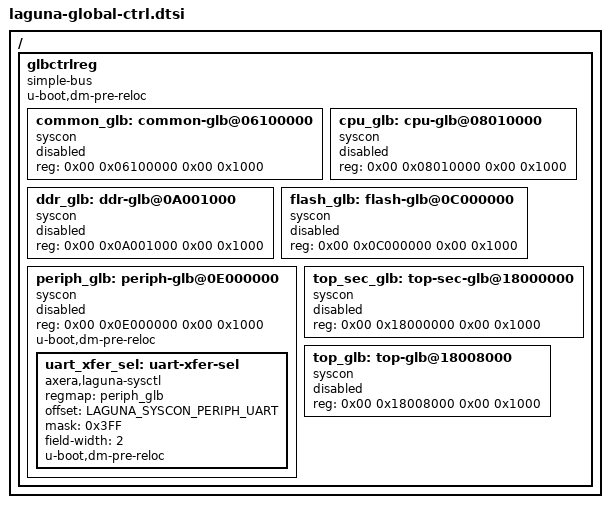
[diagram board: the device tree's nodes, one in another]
/* SPDX-License-Identifier: GPL-2.0+
 *
 * Device Tree Source for each subsystem global register region
 *
 * Copyright (C) 2024 Charleye <wangkart@aliyun.com>
 */

/ {
	glbctrlreg {
		compatible = "simple-bus";
		#address-cells = <2>;
		#size-cells = <2>;
		u-boot,dm-pre-reloc;
		u-boot,dm-spl;
		ranges;

		common_glb: common-glb@06100000 {
			compatible = "syscon", "simple-mfd";
			reg = <0x00 0x06100000 0x00 0x1000>;
			#address-cells = <1>;
			#size-cells = <1>;
			status = "disabled";
		};

		cpu_glb: cpu-glb@08010000 {
			compatible = "syscon", "simple-mfd";
			reg = <0x00 0x08010000 0x00 0x1000>;
			#address-cells = <1>;
			#size-cells = <1>;
			status = "disabled";
		};

		ddr_glb: ddr-glb@0A001000 {
			compatible = "syscon", "simple-mfd";
			reg = <0x00 0x0A001000 0x00 0x1000>;
			#address-cells = <1>;
			#size-cells = <1>;
			status = "disabled";
		};

		flash_glb: flash-glb@0C000000 {
			compatible = "syscon", "simple-mfd";
			reg = <0x00 0x0C000000 0x00 0x1000>;
			#address-cells = <1>;
			#size-cells = <1>;
			status = "disabled";
		};

		periph_glb: periph-glb@0E000000 {
			compatible = "syscon", "simple-mfd";
			reg = <0x00 0x0E000000 0x00 0x1000>;
			#address-cells = <1>;
			#size-cells = <1>;
			u-boot,dm-pre-reloc;
			u-boot,dm-spl;
			status = "disabled";

			uart_xfer_sel: uart-xfer-sel {
				compatible = "axera,laguna-sysctl";
				#syscon-cells = <2>;
				regmap = <&periph_glb>;
				offset = <LAGUNA_SYSCON_PERIPH_UART>;
				mask = <0x3FF>;
				field-width = <2>;
				u-boot,dm-pre-reloc;
				u-boot,dm-spl;
			};
		};

		top_sec_glb: top-sec-glb@18000000 {
			compatible = "syscon", "simple-mfd";
			reg = <0x00 0x18000000 0x00 0x1000>;
			#address-cells = <1>;
			#size-cells = <1>;
			status = "disabled";
		};

		top_glb: top-glb@18008000 {
			compatible = "syscon", "simple-mfd";
			reg = <0x00 0x18008000 0x00 0x1000>;
			#address-cells = <1>;
			#size-cells = <1>;
			status = "disabled";
		};
	};
};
